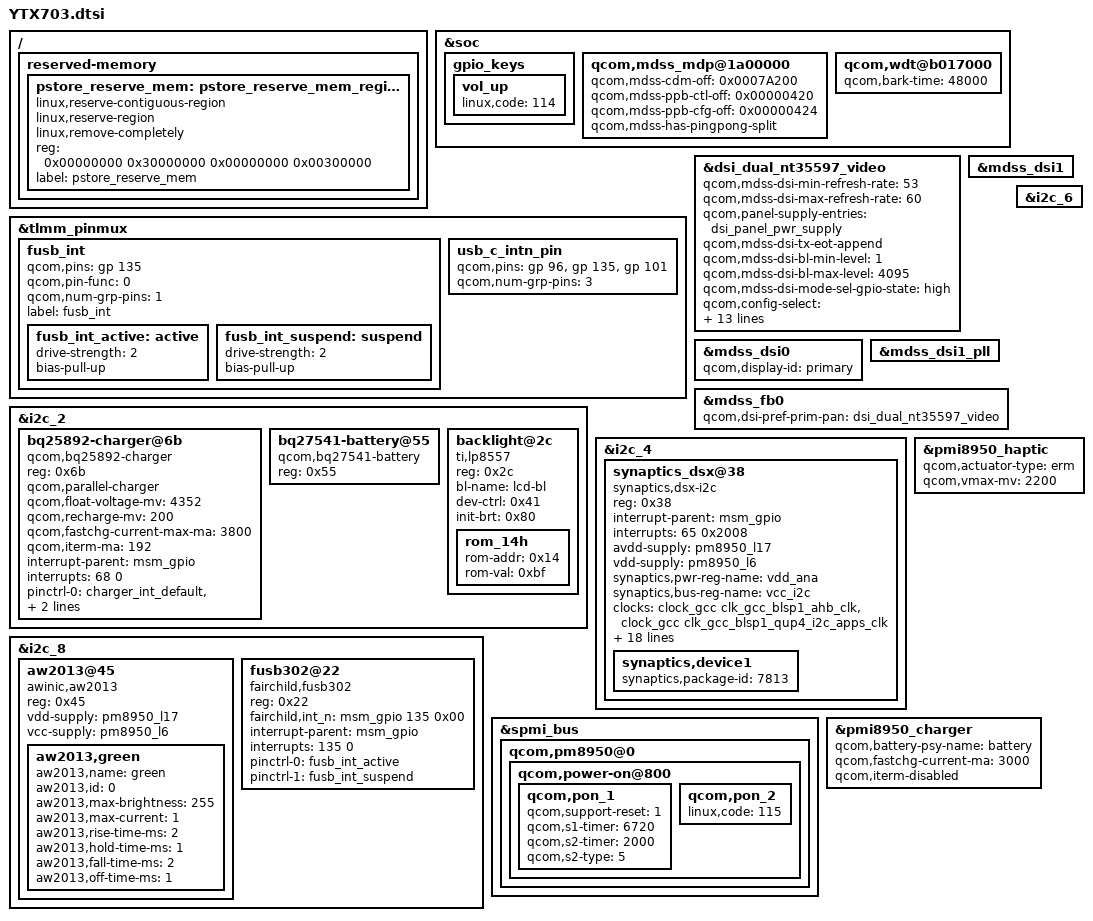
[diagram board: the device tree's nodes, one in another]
/*
 * Copyright (C) 2018 The LineageOS Project
 *
 * This program is free software; you can redistribute it and/or modify
 * it under the terms of the GNU General Public License version 2 and
 * only version 2 as published by the Free Software Foundation.
 *
 * This program is distributed in the hope that it will be useful,
 * but WITHOUT ANY WARRANTY; without even the implied warranty of
 * MERCHANTABILITY or FITNESS FOR A PARTICULAR PURPOSE.  See the
 * GNU General Public License for more details.
 */

/ {
	/* pstore: reserved DDR memory region for post-mortem kernel logs */
	reserved-memory {
		pstore_reserve_mem: pstore_reserve_mem_region@0 {
			linux,reserve-contiguous-region;
			linux,reserve-region;
			linux,remove-completely;
			reg = <0x00000000 0x30000000    /* Address */
			       0x00000000 0x00300000>;  /* Size */
			label = "pstore_reserve_mem";
		};
	};
};

&soc {
	/* Compensate for hardware-reversed VOL-UP and VOL-DOWN buttons */
	gpio_keys {
		vol_up {
			linux,code = <114>; /* KEY_VOLUMEDOWN */
		};
	};
	qcom,mdss_mdp@1a00000 {
		/delete-property/ qcom,mdss-ppb-off; //  = <0x00000420>;
		qcom,mdss-cdm-off = <0x0007A200>;
		qcom,mdss-ppb-ctl-off = <0x00000420>;
		qcom,mdss-ppb-cfg-off = <0x00000424>; // qcom,mdss-ppb-ctl-off + 4

		qcom,mdss-has-pingpong-split; // formaly known as qcom,mdss-has-dst-split;
		/delete-property/ qcom,mdss-has-source-split;
		/delete-property/ qcom,mdss-has-separate-rotator;
	};

	qcom,wdt@b017000 {
			qcom,bark-time = <48000>;
	};
};

/*
 * Pin muxing settings
 * Overrides msm8976-pinctrl.dtsi
 */
&tlmm_pinmux {
	fusb_int {
		qcom,pins = <&gp 135>;
		qcom,pin-func = <0>;
		qcom,num-grp-pins = <1>;
		label = "fusb_int";
		fusb_int_active: active {
			drive-strength = <2>; /* mA */
			bias-pull-up;
		};
		fusb_int_suspend: suspend {
			drive-strength = <2>; /* mA */
			bias-pull-up;
		};
	};
	usb_c_intn_pin {
		qcom,pins = <&gp 96>, <&gp 135>, <&gp 101>;
		qcom,num-grp-pins = <3>;
	};
};

/* LCD panel
 * - Documentation/devicetree/bindings/fb/mdss-dsi-panel.txt
 * - Overrides dsi-panel-nt35597-dualmipi-wqxga-video.dtsi
 */
&dsi_dual_nt35597_video {
	qcom,mdss-dsi-min-refresh-rate = <53>;
	qcom,mdss-dsi-max-refresh-rate = <60>;
	qcom,panel-supply-entries = <&dsi_panel_pwr_supply>;
	qcom,mdss-dsi-tx-eot-append;
	qcom,mdss-dsi-bl-min-level = <1>;
	qcom,mdss-dsi-bl-max-level = <4095>;
	/delete-property/ qcom,mdss-dsi-pan-enable-dynamic-fps;
	// /delete-property/ qcom,mdss-dsi-pan-fps-update = "dfps_immediate_porch_mode_hfp";
	qcom,mdss-dsi-mode-sel-gpio-state = "high"; // formerly known as qcom,mdss-dsi-mode-sel-gpio-state = "dsc_mode";
	qcom,config-select = <&dsi_dual_nt35597_video_config1>;
	qcom,mdss-dsi-post-init-delay = <0x1>;

	qcom,mdss-dsi-panel-width = <800>;  /* Previously 720 */
	qcom,mdss-dsi-h-front-porch = <17>; /* Horizontal front porch in pixels; previously 100 */
	qcom,mdss-dsi-h-back-porch = <30>;  /* Horizontal back porch in pixels; previously 32 */
	qcom,mdss-dsi-h-pulse-width = <4>;  /* Previously 16 */
	qcom,mdss-dsi-v-back-porch = <24>;  /* Vertical back porch in pixels; previously 7 */
	qcom,mdss-dsi-v-front-porch = <16>; /* Vertical front porch in pixels; previously 8 */
	qcom,mdss-dsi-v-pulse-width = <8>;  /* Previously 1 */
	qcom,mdss-dsi-on-command =
	       [39 01 00 00 01 00 06 f0 55 aa 52 08 00
	        15 01 00 00 01 00 02 c0 0d
	        39 01 00 00 01 00 05 b8 03 06 00 00
	        39 01 00 00 01 00 05 ff aa 55 a5 80
	        15 01 00 00 01 00 02 6f 0f
	        15 01 00 00 01 00 02 f7 01
	        39 01 00 00 01 00 05 ff aa 55 a5 00
	        15 01 00 00 01 00 02 62 01
	        15 01 00 00 01 00 02 55 00 /* CABC (0: off, 1: UI, 2: Picture, 3: Video) */
	        15 01 00 00 01 00 02 53 24
	        15 01 00 00 01 00 02 51 80
	        05 01 00 00 78 00 02 11 00
	        05 01 00 00 15 00 02 29 00];
	/* DSI PHY timings */
	qcom,mdss-dsi-panel-timings = [D5 32 22 00 60 64 26 34 29 03 04 00];
};
/*
 * Overrides msm8976-mdss-mtp.dtsi
 */
&dsi_dual_nt35597_video {
	/delete-property/ qcom,mdss-dsi-pan-enable-dynamic-fps;
	/delete-property/ qcom,mdss-dsi-pan-fps-update;
};
&mdss_dsi0 {
	status = "ok";
	qcom,display-id = "primary";
	/delete-property/ qcom,platform-bklight-en-gpio;
	/delete-property/ qcom,cont-splash-enabled;
};
&mdss_dsi1 {
	status = "ok";
	/delete-property/ qcom,platform-bklight-en-gpio;
};
&mdss_dsi1_pll {
    // qcom,dsi-pll-video-mode-fixup;
	status = "ok";
};

/*
 * Disable Linux splash screen at boot
 * Overrides msm8976-mdss.dtsi
 */
&mdss_fb0 {
	qcom,dsi-pref-prim-pan = <&dsi_dual_nt35597_video>;
	/delete-property/ qcom,mdss-fb-splash-logo-enabled;
};

/*
 * Bindings for I2C peripherals
 * Overrides msm8976-mtp.dtsi
 */
&i2c_2 {
	/delete-node/ smb1351-charger@1d;
	bq25892-charger@6b {
		compatible = "qcom,bq25892-charger";
		reg = <0x6b>;
		qcom,parallel-charger;
		qcom,float-voltage-mv = <4352>;
		qcom,recharge-mv = <200>;
		qcom,fastchg-current-max-ma = <3800>;
		qcom,iterm-ma = <192>;
		interrupt-parent = <&msm_gpio>;
		interrupts = <68 0>;
		pinctrl-names = "default";
		pinctrl-0 = <&charger_int_default &charger_psel_default>; /* Not yet defined */
		qcom,psel-gpio = <&msm_gpio 16 0>;
	};
	bq27541-battery@55 {
		compatible = "qcom,bq27541-battery";
		reg = <0x55>;
	};
	backlight@2c {
		compatible = "ti,lp8557";
		reg = <0x2c>;
		bl-name = "lcd-bl";
		dev-ctrl = /bits/ 8 <0x41>;
		init-brt = /bits/ 8 <0x80>;
		/* 4V OV, 4 output LED string enabled */
		rom_14h {
			rom-addr = /bits/ 8 <0x14>;
			rom-val = /bits/ 8 <0xbf>;
		};
	};
};
&i2c_4 {
	/delete-node/ synaptics@20;
	synaptics_dsx@38 {
		compatible = "synaptics,dsx-i2c";
		reg = <0x38>;
		interrupt-parent = <&msm_gpio>;
		interrupts = <65 0x2008>;
		avdd-supply = <&pm8950_l17>;
		vdd-supply = <&pm8950_l6>;
		synaptics,pwr-reg-name = "vdd_ana";
		synaptics,bus-reg-name = "vcc_i2c";
		clock-names = "iface_clk", "core_clk";
		clocks = <&clock_gcc clk_gcc_blsp1_ahb_clk>,
			<&clock_gcc clk_gcc_blsp1_qup4_i2c_apps_clk>;
		/* pins used by touchscreen */
		pinctrl-names = "pmx_ts_active","pmx_ts_suspend","pmx_ts_release";
		pinctrl-0 = <&ts_int_active &ts_reset_active>;
		pinctrl-1 = <&ts_int_suspend &ts_reset_suspend>;
		pinctrl-2 = <&ts_release>;
		synaptics,irq-gpio = <&msm_gpio 65 0x2008>;
		synaptics,reset-gpio = <&msm_gpio 64 0x0>;
		synaptics,i2c-pull-up;
		synaptics,power-down;
		synaptics,disable-gpios;
		synaptics,detect-device;
		synaptics,bypass-packrat-id-check;
		synaptics,power-delay-ms = <60>;
		synaptics,reset-on-state = <0>;
		synaptics,reset-active-ms = <10>;
		synaptics,reset-delay-ms = <60>;
		synaptics,ub-i2c-addr = <0x20>;
		synaptics,irq-flags = <0x2008>; /* IRQF_ONESHOT | IRQF_TRIGGER_LOW */
		synaptics,swap-axes; /* ro.sf.hwrotation=90 */
		synaptics,y-flip;
		synaptics,device1 {
			synaptics,package-id = <7813>;
		};
	};
};
&i2c_6 {
	/delete-node/ nq@2b;
};
&i2c_8 {
	aw2013@45 {
		compatible = "awinic,aw2013";
		reg = <0x45>;
		vdd-supply = <&pm8950_l17>; /* msm8976-regulator.dtsi */
		vcc-supply = <&pm8950_l6>;
		aw2013,green {
			aw2013,name = "green";
			aw2013,id = <0>;
			aw2013,max-brightness = <255>;
			aw2013,max-current = <1>;
			aw2013,rise-time-ms = <2>;
			aw2013,hold-time-ms = <1>;
			aw2013,fall-time-ms = <2>;
			aw2013,off-time-ms  = <1>;
		};
	};
	fusb302@22 {
		compatible = "fairchild,fusb302";
		reg = <0x22>;
		fairchild,int_n = <&msm_gpio 135 0x00>;
		interrupt-parent = <&msm_gpio>;
		interrupts = <135 0>; /* MSM GPIO 102 */
		interrupt-names = "fsc_interrupt_int_n";
		pinctrl-names = "fusb_active", "fusb_suspend";
		pinctrl-0 = <&fusb_int_active>;
		pinctrl-1 = <&fusb_int_suspend>;
	};
};

/* SPMI bus peripherals */
&spmi_bus {
	/*
	 * Overrides msm-pm8950.dtsi
	 */
	qcom,pm8950@0 {
		qcom,power-on@800 {
			/* Power button */
			qcom,pon_1 {
				qcom,support-reset = <1>;
				qcom,s1-timer = <6720>; /* button delay until poweroff */
				qcom,s2-timer = <2000>; /* button delay until reboot */
				qcom,s2-type = <5>;
			};
			/* Compensate for hardware-reversed VOL-UP and VOL-DOWN buttons */
			qcom,pon_2 {
				linux,code = <115>; /* KEY_VOLUMEUP */
			};
		};
	};
};
/*
 * Vibration motor
 * Overrides:
 * - msm-pmi8950.dtsi
 * - msm8976-mtp.dtsi
 */
&pmi8950_haptic {
	qcom,actuator-type = "erm";
	qcom,vmax-mv = <2200>;
};
/*
 * Charger
 * Overrides msm-pmi8950.dtsi
 */
&pmi8950_charger {
	qcom,battery-psy-name= "battery";
	qcom,fastchg-current-ma = <3000>;
	qcom,iterm-disabled;
	/delete-property/ qcom,iterm-ma;
	/delete-property/ qcom,float-voltage-mv;
	/delete-property/ qcom,resume-delta-mv;
	/delete-property/ qcom,autoadjust-vfloat;
	/delete-property/ qcom,force-aicl-rerun;
	/delete-property/ qcom,aicl-rerun-period-s;
	/delete-property/ qcom,charging-disabled;
};

